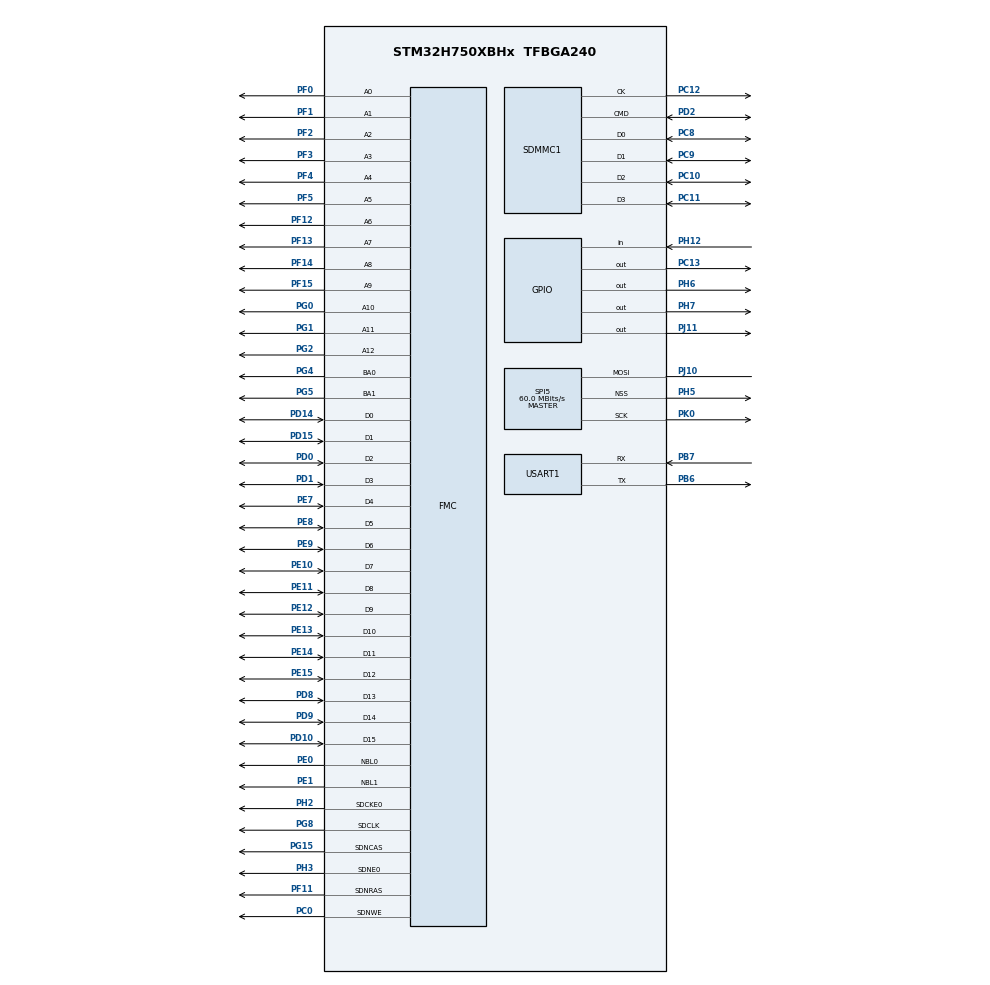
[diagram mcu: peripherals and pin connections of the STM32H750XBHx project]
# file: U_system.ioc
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CORTEX_M7.AccessPermission-Cortex_Memory_Protection_Unit_Region0_Settings=MPU_REGION_FULL_ACCESS
CORTEX_M7.BaseAddress-Cortex_Memory_Protection_Unit_Region0_Settings=0xC0000000
CORTEX_M7.BaseAddress_Spec=0xC0000000
CORTEX_M7.CPU_DCache=Disabled
CORTEX_M7.CPU_ICache=Enabled
CORTEX_M7.DisableExec_Spec=MPU_INSTRUCTION_ACCESS_ENABLE
CORTEX_M7.Enable-Cortex_Memory_Protection_Unit_Region0_Settings=MPU_REGION_ENABLE
CORTEX_M7.IsCacheable-Cortex_Memory_Protection_Unit_Region0_Settings=MPU_ACCESS_CACHEABLE
CORTEX_M7.IsCacheable_Spec=MPU_ACCESS_CACHEABLE
CORTEX_M7.IsShareable_Spec=MPU_ACCESS_NOT_SHAREABLE
CORTEX_M7.MPU_Control=MPU_PRIVILEGED_DEFAULT
CORTEX_M7.Size-Cortex_Memory_Protection_Unit_Region0_Settings=MPU_REGION_SIZE_32MB
CORTEX_M7.Size_Spec=MPU_REGION_SIZE_32MB
CORTEX_M7.SubRegionDisable_Spec=0x0
DMA2D.ColorMode=DMA2D_OUTPUT_RGB565
DMA2D.Mode=DMA2D_M2M
FATFS._CODE_PAGE=437
FATFS._FS_LOCK=0
FATFS._FS_NORTC=1
FATFS._MAX_SS=4096
FATFS._NORTC_MDAY=1
FATFS._NORTC_MON=5
FATFS._NORTC_YEAR=2017
FATFS._USE_FASTSEEK=0
FATFS._USE_LFN=2
FATFS._USE_MKFS=1
FATFS._USE_STRFUNC=0
FATFS._VOLUMES=2
FMC.CASLatency1=FMC_SDRAM_CAS_LATENCY_3
FMC.ColumnBitsNumber1=FMC_SDRAM_COLUMN_BITS_NUM_9
FMC.ExitSelfRefreshDelay1=7
FMC.LoadToActiveDelay1=2
FMC.RCDDelay1=2
FMC.RPDelay1=2
FMC.ReadBurst1=FMC_SDRAM_RBURST_ENABLE
FMC.ReadPipeDelay1=FMC_SDRAM_RPIPE_DELAY_1
FMC.RowCycleDelay1=7
FMC.SDClockPeriod1=FMC_SDRAM_CLOCK_PERIOD_2
FMC.SelfRefreshTime1=4
FMC.WriteRecoveryTime1=3
FREERTOS.Tasks01=VirtualBash,0,128,Shell,Default,NULL,Dynamic,NULL,NULL;LCD,1,512,LCD_Display,Default,NULL,Dynamic,NULL,NULL;FIleSystem,0,1024,FatFsTask,Default,NULL,Dynamic,NULL,NULL;VirtualFileSyst,0,1024,VFS,Default,NULL,Dynamic,NULL,NULL
FREERTOS.configENABLE_FPU=1
FREERTOS.configTOTAL_HEAP_SIZE=20480
FREERTOS.configUSE_NEWLIB_REENTRANT=1
HASH.SecureHashAlgorithmType=SHA256
JPEG.JPEG_RGB_FORMAT=JPEG_RGB565
Mcu.Family=STM32H7
Mcu.Name=STM32H750XBHx
Mcu.Package=TFBGA240
NVIC.PriorityGroup=NVIC_PRIORITYGROUP_4
NVIC.SDMMC1_IRQn=true\:14\:0\:true\:false\:true\:true\:true\:true\:true
NVIC.TIM1_UP_IRQn=true\:15\:0\:false\:false\:true\:false\:false\:true\:true
NVIC.TimeBase=TIM1_UP_IRQn
NVIC.TimeBaseIP=TIM1
PA13\ (JTMS/SWDIO).Mode=Serial_Wire
PA13\ (JTMS/SWDIO).Signal=DEBUG_JTMS-SWDIO
PA14\ (JTCK/SWCLK).Mode=Serial_Wire
PA14\ (JTCK/SWCLK).Signal=DEBUG_JTCK-SWCLK
PB6.GPIO_Speed=GPIO_SPEED_FREQ_VERY_HIGH
PB6.Mode=Asynchronous
PB6.Signal=USART1_TX
PB7.GPIO_Speed=GPIO_SPEED_FREQ_VERY_HIGH
PB7.Mode=Asynchronous
PB7.Signal=USART1_RX
PC0.Signal=FMC_SDNWE
PC10.Mode=SD_4_bits_Wide_bus
PC10.Signal=SDMMC1_D2
PC11.Mode=SD_4_bits_Wide_bus
PC11.Signal=SDMMC1_D3
PC12.Mode=SD_4_bits_Wide_bus
PC12.Signal=SDMMC1_CK
PC13.Signal=GPIO_Output
PC14-OSC32_IN\ (OSC32_IN).Mode=LSE-External-Oscillator
PC14-OSC32_IN\ (OSC32_IN).Signal=RCC_OSC32_IN
PC15-OSC32_OUT\ (OSC32_OUT).Mode=LSE-External-Oscillator
PC15-OSC32_OUT\ (OSC32_OUT).Signal=RCC_OSC32_OUT
PC8.Mode=SD_4_bits_Wide_bus
PC8.Signal=SDMMC1_D0
PC9.Mode=SD_4_bits_Wide_bus
PC9.Signal=SDMMC1_D1
PD0.Signal=FMC_D2_DA2
PD1.Signal=FMC_D3_DA3
PD10.Signal=FMC_D15_DA15
PD14.Signal=FMC_D0_DA0
PD15.Signal=FMC_D1_DA1
PD2.Mode=SD_4_bits_Wide_bus
PD2.Signal=SDMMC1_CMD
PD8.Signal=FMC_D13_DA13
PD9.Signal=FMC_D14_DA14
PE0.Signal=FMC_NBL0
PE1.Signal=FMC_NBL1
PE10.Signal=FMC_D7_DA7
PE11.Signal=FMC_D8_DA8
PE12.Signal=FMC_D9_DA9
PE13.Signal=FMC_D10_DA10
PE14.Signal=FMC_D11_DA11
PE15.Signal=FMC_D12_DA12
PE7.Signal=FMC_D4_DA4
PE8.Signal=FMC_D5_DA5
PE9.Signal=FMC_D6_DA6
PF0.Signal=FMC_A0
PF1.Signal=FMC_A1
PF11.Signal=FMC_SDNRAS
PF12.Signal=FMC_A6
PF13.Signal=FMC_A7
PF14.Signal=FMC_A8
PF15.Signal=FMC_A9
PF2.Signal=FMC_A2
PF3.Signal=FMC_A3
PF4.Signal=FMC_A4
PF5.Signal=FMC_A5
PG0.Signal=FMC_A10
PG1.Signal=FMC_A11
PG15.Signal=FMC_SDNCAS
PG2.Signal=FMC_A12
PG4.Signal=FMC_A14_BA0
PG5.Signal=FMC_A15_BA1
PG8.Signal=FMC_SDCLK
PH0-OSC_IN\ (PH0).Mode=HSE-External-Oscillator
PH0-OSC_IN\ (PH0).Signal=RCC_OSC_IN
PH1-OSC_OUT\ (PH1).Mode=HSE-External-Oscillator
PH1-OSC_OUT\ (PH1).Signal=RCC_OSC_OUT
PH12.Signal=GPIO_Input
PH2.Mode=SdramChipSelect1_1
PH2.Signal=FMC_SDCKE0
PH3.Mode=SdramChipSelect1_1
PH3.Signal=FMC_SDNE0
PH5.GPIO_Speed=GPIO_SPEED_FREQ_VERY_HIGH
PH5.Mode=NSS_Signal_Hard_Output
PH5.Signal=SPI5_NSS
PH6.Signal=GPIO_Output
PH7.Signal=GPIO_Output
PJ10.GPIO_Speed=GPIO_SPEED_FREQ_VERY_HIGH
PJ10.Mode=Simplex_Bidirectional_Master
PJ10.Signal=SPI5_MOSI
PJ11.Signal=GPIO_Output
PK0.GPIO_Speed=GPIO_SPEED_FREQ_VERY_HIGH
PK0.Mode=Simplex_Bidirectional_Master
PK0.Signal=SPI5_SCK
ProjectManager.HeapSize=0x1000
ProjectManager.StackSize=0x2000
ProjectManager.TargetToolchain=STM32CubeIDE
RCC.ADCFreq_Value=480000000
RCC.APB1Freq_Value=120000000
RCC.APB2Freq_Value=120000000
RCC.APB3Freq_Value=120000000
RCC.APB4Freq_Value=120000000
RCC.CortexFreq_Value=480000000
RCC.D1PPRE=RCC_APB3_DIV2
RCC.D2PPRE1=RCC_APB1_DIV2
RCC.D2PPRE2=RCC_APB2_DIV2
RCC.D3PPRE=RCC_APB4_DIV2
RCC.DIVM1=5
RCC.DIVM2=5
RCC.DIVM3=5
RCC.DIVN1=192
RCC.DIVN2=192
RCC.DIVN3=192
RCC.DIVQ1=4
RCC.HCLKFreq_Value=240000000
RCC.HPRE=RCC_HCLK_DIV2
RCC.PLLSourceVirtual=RCC_PLLSOURCE_HSE
RCC.SYSCLKFreq_VALUE=480000000
RCC.SYSCLKSource=RCC_SYSCLKSOURCE_PLLCLK
RCC.USBFreq_Value=240000000
SDMMC1.ClockDiv=6
SH.FMC_A0.0=FMC_A0,13b-sda1
SH.FMC_A1.0=FMC_A1,13b-sda1
SH.FMC_A10.0=FMC_A10,13b-sda1
SH.FMC_A11.0=FMC_A11,13b-sda1
SH.FMC_A12.0=FMC_A12,13b-sda1
SH.FMC_A14_BA0.0=FMC_BA0,FourSdramBanks1
SH.FMC_A15_BA1.0=FMC_BA1,FourSdramBanks1
SH.FMC_A2.0=FMC_A2,13b-sda1
SH.FMC_A3.0=FMC_A3,13b-sda1
SH.FMC_A4.0=FMC_A4,13b-sda1
SH.FMC_A5.0=FMC_A5,13b-sda1
SH.FMC_A6.0=FMC_A6,13b-sda1
SH.FMC_A7.0=FMC_A7,13b-sda1
SH.FMC_A8.0=FMC_A8,13b-sda1
SH.FMC_A9.0=FMC_A9,13b-sda1
SH.FMC_D0_DA0.0=FMC_D0,sd-16b-d1
SH.FMC_D10_DA10.0=FMC_D10,sd-16b-d1
SH.FMC_D11_DA11.0=FMC_D11,sd-16b-d1
SH.FMC_D12_DA12.0=FMC_D12,sd-16b-d1
SH.FMC_D13_DA13.0=FMC_D13,sd-16b-d1
SH.FMC_D14_DA14.0=FMC_D14,sd-16b-d1
SH.FMC_D15_DA15.0=FMC_D15,sd-16b-d1
SH.FMC_D1_DA1.0=FMC_D1,sd-16b-d1
SH.FMC_D2_DA2.0=FMC_D2,sd-16b-d1
SH.FMC_D3_DA3.0=FMC_D3,sd-16b-d1
SH.FMC_D4_DA4.0=FMC_D4,sd-16b-d1
SH.FMC_D5_DA5.0=FMC_D5,sd-16b-d1
SH.FMC_D6_DA6.0=FMC_D6,sd-16b-d1
SH.FMC_D7_DA7.0=FMC_D7,sd-16b-d1
SH.FMC_D8_DA8.0=FMC_D8,sd-16b-d1
SH.FMC_D9_DA9.0=FMC_D9,sd-16b-d1
SH.FMC_NBL0.0=FMC_NBL0,Sd2ByteEnable1
SH.FMC_NBL1.0=FMC_NBL1,Sd2ByteEnable1
SH.FMC_SDCLK.0=FMC_SDCLK,13b-sda1
SH.FMC_SDNCAS.0=FMC_SDNCAS,13b-sda1
SH.FMC_SDNRAS.0=FMC_SDNRAS,13b-sda1
SH.FMC_SDNWE.0=FMC_SDNWE,13b-sda1
SPI5.CalculateBaudRate=60.0 MBits/s
SPI5.DataSize=SPI_DATASIZE_8BIT
SPI5.Direction=SPI_DIRECTION_1LINE
SPI5.FifoThreshold=SPI_FIFO_THRESHOLD_02DATA
SPI5.Mode=SPI_MODE_MASTER
SPI5.VirtualNSS=VM_NSSHARD
SPI5.VirtualType=VM_MASTER
USART1.VirtualMode-Asynchronous=VM_ASYNC
VP_DMA2D_VS_DMA2D.Mode=DMA2D_Activate
VP_FATFS_VS_SDIO.Mode=SDIO
VP_FREERTOS_VS_CMSIS_V1.Mode=CMSIS_V1
VP_HASH_VS_HASH.Mode=HASH_Activate
VP_JPEG_VS_JPEG.Mode=JPEG_Activate
VP_RNG_VS_RNG.Mode=RNG_Activate
VP_RTC_VS_RTC_Activate.Mode=RTC_Enabled
VP_SYS_VS_tim1.Mode=TIM1
board=custom

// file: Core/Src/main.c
/* USER CODE BEGIN Header */
/**
  ******************************************************************************
  * @file           : main.c
  * @brief          : Main program body
  ******************************************************************************
  * @attention
  *
  * Copyright (c) 2024 STMicroelectronics.
  * All rights reserved.
  *
  * This software is licensed under terms that can be found in the LICENSE file
  * in the root directory of this software component.
  * If no LICENSE file comes with this software, it is provided AS-IS.
  *
  ******************************************************************************
  */
/* USER CODE END Header */
#include "main.h"
#include "cmsis_os.h"
#include "dma2d.h"
#include "fatfs.h"
#include "hash.h"
#include "jpeg.h"
#include "rng.h"
#include "rtc.h"
#include "sdmmc.h"
#include "spi.h"
#include "usart.h"
#include "gpio.h"
#include "fmc.h"

void SystemClock_Config(void);
static void MPU_Initialize(void);
static void MPU_Config(void);
void MX_FREERTOS_Init(void);

int main(void)
{

  /* Enable I-Cache---------------------------------------------------------*/
  SCB_EnableICache();

  /* MCU Configuration--------------------------------------------------------*/

  /* Reset of all peripherals, Initializes the Flash interface and the Systick. */
  HAL_Init();

  /* MPU Configuration--------------------------------------------------------*/
  MPU_Config();

  /* Configure the system clock */
  SystemClock_Config();

  /* Initialize all configured peripherals */
  MX_GPIO_Init();
  MX_USART1_UART_Init();
  MX_FMC_Init();
  MX_RTC_Init();
  MX_SDMMC1_SD_Init();
  MX_JPEG_Init();
  MX_DMA2D_Init();
  MX_SPI5_Init();
  MX_FATFS_Init();
  MX_HASH_Init();
  MX_RNG_Init();
  /* USER CODE BEGIN 2 */
  // SCB_DisableDCache();
  /* USER CODE END 2 */

  /* Call init function for freertos objects (in freertos.c) */
  MX_FREERTOS_Init();

  /* Start scheduler */
  osKernelStart();

  /* We should never get here as control is now taken by the scheduler */
  /* Infinite loop */
  while (1)
  {

  }
}

void SystemClock_Config(void)
{
  RCC_OscInitTypeDef RCC_OscInitStruct = {0};
  RCC_ClkInitTypeDef RCC_ClkInitStruct = {0};

  /** Supply configuration update enable
  */
  HAL_PWREx_ConfigSupply(PWR_LDO_SUPPLY);

  /** Configure the main internal regulator output voltage
  */

  while(!__HAL_PWR_GET_FLAG(PWR_FLAG_VOSRDY)) {}

  /** Initializes the RCC Oscillators according to the specified parameters
  * in the RCC_OscInitTypeDef structure.
  */
  RCC_OscInitStruct.OscillatorType = RCC_OSCILLATORTYPE_HSI48|RCC_OSCILLATORTYPE_LSI
                              |RCC_OSCILLATORTYPE_HSE;
  RCC_OscInitStruct.HSEState = RCC_HSE_ON;
  RCC_OscInitStruct.LSIState = RCC_LSI_ON;
  RCC_OscInitStruct.HSI48State = RCC_HSI48_ON;
  RCC_OscInitStruct.PLL.PLLState = RCC_PLL_ON;
  RCC_OscInitStruct.PLL.PLLSource = RCC_PLLSOURCE_HSE;
  RCC_OscInitStruct.PLL.PLLM = 5;
  RCC_OscInitStruct.PLL.PLLN = 192;
  RCC_OscInitStruct.PLL.PLLP = 2;
  RCC_OscInitStruct.PLL.PLLQ = 4;
  RCC_OscInitStruct.PLL.PLLR = 2;
  RCC_OscInitStruct.PLL.PLLRGE = RCC_PLL1VCIRANGE_2;
  RCC_OscInitStruct.PLL.PLLVCOSEL = RCC_PLL1VCOWIDE;
  RCC_OscInitStruct.PLL.PLLFRACN = 0;
  if (HAL_RCC_OscConfig(&RCC_OscInitStruct) != HAL_OK)
  {
    Error_Handler();
  }

  /** Initializes the CPU, AHB and APB buses clocks
  */
  RCC_ClkInitStruct.ClockType = RCC_CLOCKTYPE_HCLK|RCC_CLOCKTYPE_SYSCLK
                              |RCC_CLOCKTYPE_PCLK1|RCC_CLOCKTYPE_PCLK2
                              |RCC_CLOCKTYPE_D3PCLK1|RCC_CLOCKTYPE_D1PCLK1;
  RCC_ClkInitStruct.SYSCLKSource = RCC_SYSCLKSOURCE_PLLCLK;
  RCC_ClkInitStruct.SYSCLKDivider = RCC_SYSCLK_DIV1;
  RCC_ClkInitStruct.AHBCLKDivider = RCC_HCLK_DIV2;
  RCC_ClkInitStruct.APB3CLKDivider = RCC_APB3_DIV2;
  RCC_ClkInitStruct.APB1CLKDivider = RCC_APB1_DIV2;
  RCC_ClkInitStruct.APB2CLKDivider = RCC_APB2_DIV2;
  RCC_ClkInitStruct.APB4CLKDivider = RCC_APB4_DIV2;

  if (HAL_RCC_ClockConfig(&RCC_ClkInitStruct, FLASH_LATENCY_0) != HAL_OK)
  {
    Error_Handler();
  }
}

/* MPU Configuration */

void MPU_Config(void)
{
  MPU_Region_InitTypeDef MPU_InitStruct = {0};

  /* Disables the MPU */
  HAL_MPU_Disable();

  /** Initializes and configures the Region and the memory to be protected
  */
  MPU_InitStruct.Enable = MPU_REGION_ENABLE;
  MPU_InitStruct.Number = MPU_REGION_NUMBER0;
  MPU_InitStruct.BaseAddress = 0xC0000000;
  MPU_InitStruct.Size = MPU_REGION_SIZE_32MB;
  MPU_InitStruct.SubRegionDisable = 0x0;
  MPU_InitStruct.TypeExtField = MPU_TEX_LEVEL0;
  MPU_InitStruct.AccessPermission = MPU_REGION_FULL_ACCESS;
  MPU_InitStruct.DisableExec = MPU_INSTRUCTION_ACCESS_ENABLE;
  MPU_InitStruct.IsShareable = MPU_ACCESS_NOT_SHAREABLE;
  MPU_InitStruct.IsCacheable = MPU_ACCESS_CACHEABLE;
  MPU_InitStruct.IsBufferable = MPU_ACCESS_NOT_BUFFERABLE;

  HAL_MPU_ConfigRegion(&MPU_InitStruct);
  /* Enables the MPU */
  HAL_MPU_Enable(MPU_PRIVILEGED_DEFAULT);

}

void HAL_TIM_PeriodElapsedCallback(TIM_HandleTypeDef *htim)
{
  if (htim->Instance == TIM1) {
    HAL_IncTick();
  }
}

void Error_Handler(void)
{
  __disable_irq();
  while (1)
  {
  }
}

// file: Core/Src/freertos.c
/* USER CODE BEGIN Header */
/**
  ******************************************************************************
  * File Name          : freertos.c
  * Description        : Code for freertos applications
  ******************************************************************************
  * @attention
  *
  * Copyright (c) 2024 STMicroelectronics.
  * All rights reserved.
  *
  * This software is licensed under terms that can be found in the LICENSE file
  * in the root directory of this software component.
  * If no LICENSE file comes with this software, it is provided AS-IS.
  *
  ******************************************************************************
  */
/* USER CODE END Header */

#include "FreeRTOS.h"
#include "task.h"
#include "main.h"
#include "cmsis_os.h"

/* USER CODE BEGIN Includes */
#include "application.h"
#include "../../Task/inc/taskHead.h"
#include "fmc.h"
#include "u_stdio.h"
/* USER CODE END Includes */

osThreadId VirtualBashHandle;
osThreadId LCDHandle;
osThreadId FIleSystemHandle;
osThreadId VirtualFileSystHandle;

void Shell(void const * argument);
void LCD_Display(void const * argument);
void FatFsTask(void const * argument);
void VFS(void const * argument);

void MX_FREERTOS_Init(void); /* (MISRA C 2004 rule 8.1) */

/* GetIdleTaskMemory prototype (linked to static allocation support) */
void vApplicationGetIdleTaskMemory( StaticTask_t **ppxIdleTaskTCBBuffer, StackType_t **ppxIdleTaskStackBuffer, uint32_t *pulIdleTaskStackSize );

/* USER CODE BEGIN GET_IDLE_TASK_MEMORY */
static StaticTask_t xIdleTaskTCBBuffer;
static StackType_t xIdleStack[configMINIMAL_STACK_SIZE];

void vApplicationGetIdleTaskMemory( StaticTask_t **ppxIdleTaskTCBBuffer, StackType_t **ppxIdleTaskStackBuffer, uint32_t *pulIdleTaskStackSize )
{
  *ppxIdleTaskTCBBuffer = &xIdleTaskTCBBuffer;
  *ppxIdleTaskStackBuffer = &xIdleStack[0];
  *pulIdleTaskStackSize = configMINIMAL_STACK_SIZE;
  /* place for user code */
}
/* USER CODE END GET_IDLE_TASK_MEMORY */

void MX_FREERTOS_Init(void) {

  /* Create the thread(s) */
  /* definition and creation of VirtualBash */
  osThreadDef(VirtualBash, Shell, osPriorityNormal, 0, 128);
  VirtualBashHandle = osThreadCreate(osThread(VirtualBash), NULL);

  /* definition and creation of LCD */
  osThreadDef(LCD, LCD_Display, osPriorityAboveNormal, 0, 512);
  LCDHandle = osThreadCreate(osThread(LCD), NULL);

  /* definition and creation of FIleSystem */
  osThreadDef(FIleSystem, FatFsTask, osPriorityNormal, 0, 1024);
  FIleSystemHandle = osThreadCreate(osThread(FIleSystem), NULL);

  /* definition and creation of VirtualFileSyst */
  osThreadDef(VirtualFileSyst, VFS, osPriorityNormal, 0, 1024);
  VirtualFileSystHandle = osThreadCreate(osThread(VirtualFileSyst), NULL);

  /* USER CODE BEGIN RTOS_THREADS */
  /* add threads, ... */
  SPI_LCD_Init();
  SDRAM_Initialization_Sequence(&hsdram1);
  /* USER CODE END RTOS_THREADS */

}

void Shell(void const * argument)
{
  /* USER CODE BEGIN Shell */
  /* Infinite loop */
  for(;;)
  {
      // 这句话不能少，否则会导致串口输出异常
     osDelay(1);
  }
  /* USER CODE END Shell */
}

void LCD_Display(void const * argument)
{
  /* USER CODE BEGIN LCD_Display */
  /* Infinite loop */

  LCD_Task_Init();
  while(1)
      LCD_main();
  /* USER CODE END LCD_Display */
}

void FatFsTask(void const * argument)
{
  /* USER CODE BEGIN FatFsTask */
  /* Infinite loop */
  for(;;){
      // FatFs_Check();
  }
  /* USER CODE END FatFsTask */
}

void VFS(void const * argument)
{
  /* USER CODE BEGIN VFS */
  /* Infinite loop */
  ram_init();
  for(;;){
      ram_main();
      // SDRAM_Test();
  }
  /* USER CODE END VFS */
}
